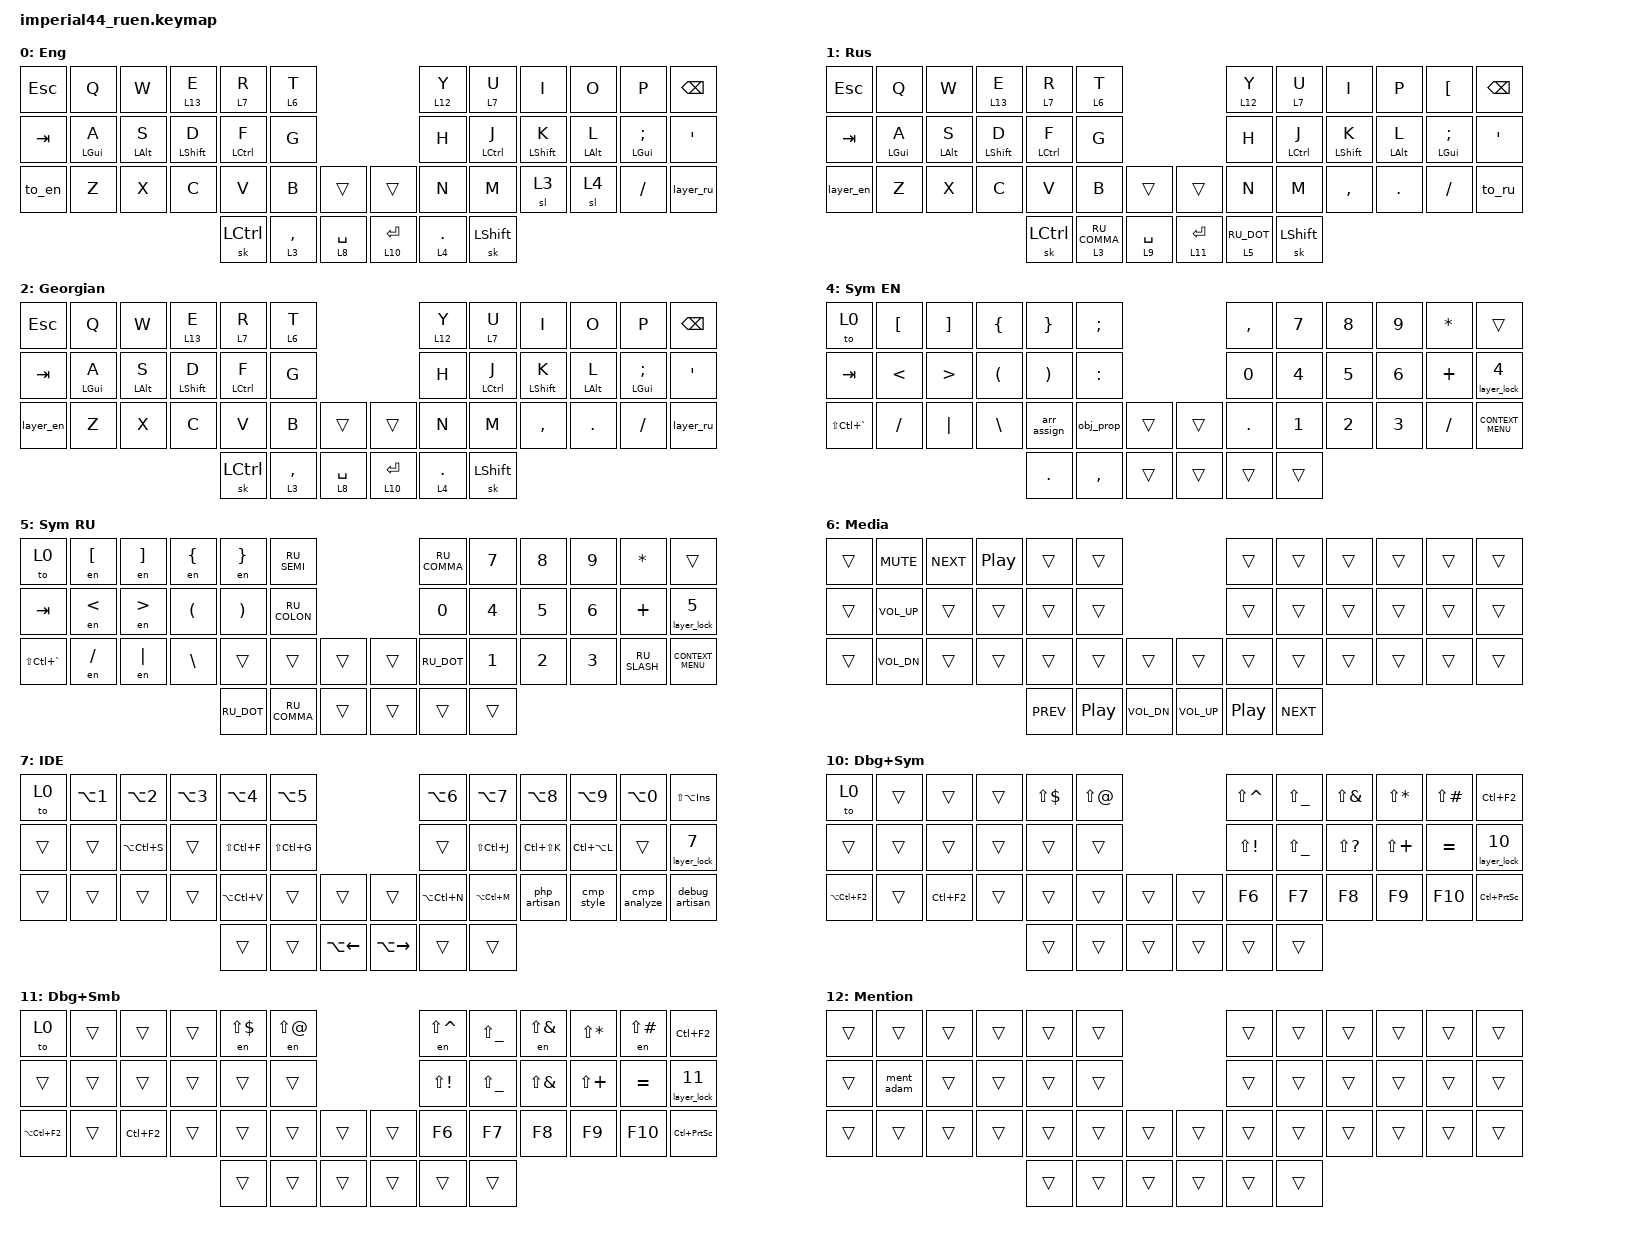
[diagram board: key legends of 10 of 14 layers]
#include "keys_ru.h"
#include <behaviors.dtsi>
#include <dt-bindings/zmk/keys.h>
#include <dt-bindings/zmk/pointing.h>

/ {
    combos {
        compatible = "zmk,combos";

        combo_cut {
            bindings = <&kp LC(X)>;
            key-positions = <26 27>;
            layers = <0 1>;
        };

        combo_copy {
            bindings = <&kp LC(C)>;
            key-positions = <27 28>;
            layers = <0 1>;
        };

        combo_paste {
            bindings = <&kp LC(V)>;
            key-positions = <28 38>;
            layers = <0 1>;
        };

        combo_dash {
            bindings = <&kp MINUS>;
            key-positions = <4 5>;
            layers = <0 1>;
            timeout-ms = <30>;
        };

        combo_grave {
            bindings = <&kp GRAVE>;
            key-positions = <4 3>;
            layers = <0 1>;
            timeout-ms = <30>;
        };

        combo_underscore {
            bindings = <&kp UNDER>;
            key-positions = <6 7>;
            layers = <0 1>;
            timeout-ms = <30>;
        };

        combo_ru_scha {
            bindings = <&kp O>;
            key-positions = <7 8>;
            layers = <1>;
        };

        combo_ru_hard_b {
            bindings = <&kp RIGHT_BRACKET>;
            key-positions = <33 34>;
            layers = <1>;
        };

        geo_lng {
            bindings = <&layer_ge>;
            key-positions = <37 36>;
            layers = <0 1 2>;
        };
    };

    macros {
        to_ru: to_ru {
            compatible = "zmk,behavior-macro";
            #binding-cells = <0>;
            bindings = <&kp LS(LC(N2))>;
            label = "TO_RU";
            wait-ms = <0>;
            tap-ms = <30>;
        };

        to_en: to_en {
            compatible = "zmk,behavior-macro";
            #binding-cells = <0>;
            bindings = <&kp LS(LC(N1))>;
            label = "TO_EN";
            wait-ms = <0>;
            tap-ms = <30>;
        };

        layer_en: layer_en {
            compatible = "zmk,behavior-macro";
            #binding-cells = <0>;
            bindings = <&to 0 &to_en>;
            label = "LAYER_EN";
            wait-ms = <0>;
            tap-ms = <30>;
        };

        layer_ru: layer_ru {
            compatible = "zmk,behavior-macro";
            #binding-cells = <0>;
            bindings = <&to 1 &to_ru>;
            label = "LAYER_RU";
            tap-ms = <30>;
            wait-ms = <0>;
        };

        en: en {
            compatible = "zmk,behavior-macro-one-param";
            #binding-cells = <1>;
            bindings =
                <&to_en>,
                <&macro_press>,
                <&macro_param_1to1 &kp MACRO_PLACEHOLDER>,
                <&macro_pause_for_release>,
                <&macro_release>,
                <&macro_param_1to1 &kp MACRO_PLACEHOLDER>,
                <&macro_tap>,
                <&to_ru>;

            label = "EN";
            wait-ms = <0>;
            tap-ms = <30>;
        };

        row_: row_ {
            compatible = "zmk,behavior-macro-one-param";
            #binding-cells = <1>;
            bindings = <&kp HOME &kp LS(END) &macro_param_1to1 &kp MACRO_PLACEHOLDER>;
            label = "ROW_";
        };

        row_copy: row_copy {
            compatible = "zmk,behavior-macro";
            #binding-cells = <0>;
            bindings = <&row_ LC(C)>;
            label = "ROW_COPY";
        };

        row_cut: row_cut {
            compatible = "zmk,behavior-macro";
            #binding-cells = <0>;
            bindings = <&row_ LC(X)>;
            label = "ROW_CUT";
        };

        arr_assign: arr_assign {
            compatible = "zmk,behavior-macro";
            #binding-cells = <0>;
            bindings = <&to_en &kp EQUAL &kp GREATER_THAN>;
            label = "ARR_ASSIGN";
        };

        obj_prop: obj_prop {
            compatible = "zmk,behavior-macro";
            #binding-cells = <0>;
            bindings = <&to_en &kp MINUS &kp GT>;
            label = "OBJ_PROP";
        };

        php_artisan: php_artisan {
            compatible = "zmk,behavior-macro";
            #binding-cells = <0>;
            bindings = <&to_en &kp P &kp H &kp P &kp SPACE &kp A &kp R &kp T &kp I &kp S &kp A &kp N &kp SPACE>;
            label = "PHP_ARTISAN";
        };

        cmp_style: cmp_style {
            compatible = "zmk,behavior-macro";
            #binding-cells = <0>;
            bindings = <&to_en &kp C &kp O &kp M &kp P &kp O &kp S &kp E &kp R &kp SPACE &kp S &kp T &kp Y &kp L &kp E>;
            label = "CMP_STYLE";
        };

        cmp_analyze: cmp_analyze {
            compatible = "zmk,behavior-macro";
            #binding-cells = <0>;
            bindings = <&to_en &kp C &kp O &kp M &kp P &kp O &kp S &kp E &kp R &kp SPACE &kp A &kp N &kp A &kp L &kp Y &kp Z &kp E>;
            label = "CMP_ANALYZE";
        };

        ment_adam: ment_adam {
            compatible = "zmk,behavior-macro";
            #binding-cells = <0>;
            bindings = <&kp AT &kp LS(A) &kp D &kp A &kp M>;
            label = "MENT_ADAM";
        };

        arr_assign_ru: arr_assign_ru {
            compatible = "zmk,behavior-macro";
            #binding-cells = <0>;
            bindings = <&to_en &kp EQUAL &kp GREATER_THAN &to_ru>;
            label = "ARR_ASSIGN_RU";
        };

        obj_prop_ru: obj_prop_ru {
            compatible = "zmk,behavior-macro";
            #binding-cells = <0>;
            bindings = <&to_en &kp MINUS &kp GT &to_ru>;
            label = "OBJ_PROP_RU";
        };

        debug_artisan: debug_artisan {
            compatible = "zmk,behavior-macro";
            #binding-cells = <0>;
            bindings = <&kp P &kp H &kp P &kp MINUS &kp D &kp SPACE &kp A &kp R &kp T &kp I &kp S &kp A &kp N &kp SPACE>;
            label = "DEBUG_ARTISAN";
        };

        to_ge: to_ge {
            compatible = "zmk,behavior-macro";
            #binding-cells = <0>;
            bindings = <&kp LS(LC(N3))>;
            label = "TO_GE";
            wait-ms = <0>;
            tap-ms = <30>;
        };

        layer_ge: layer_ge {
            compatible = "zmk,behavior-macro";
            #binding-cells = <0>;
            bindings = <&to 2 &to_ge>;
            label = "LAYER_GE";
            tap-ms = <30>;
            wait-ms = <0>;
        };
    };

    behaviors {
        hrm: hrm {
            compatible = "zmk,behavior-hold-tap";
            label = "HRM";
            bindings = <&kp>, <&kp>;

            #binding-cells = <2>;
            tapping-term-ms = <200>;
            flavor = "tap-preferred";
            require-prior-idle-ms = <125>;
            quick-tap-ms = <200>;
        };

        row_cut_copy: row_cut_copy {
            compatible = "zmk,behavior-tap-dance";
            label = "ROW_CUT_COPY";
            #binding-cells = <0>;
            bindings = <&row_copy>, <&row_cut>;
        };

        tog_layer_on: tog_layer_on {
            compatible = "zmk,behavior-toggle-layer";
            label = "TOG_LAYER_ON";
            #binding-cells = <1>;
        };

        layer_lock: layer_lock {
            compatible = "zmk,behavior-toggle-layer";
            label = "LAYER_LOCK";
            #binding-cells = <1>;
            toggle-mode = "on";
            locking;
        };
    };

    keymap {
        compatible = "zmk,keymap";

        en {
            bindings = <
&kp ESC  &kp Q            &kp W            &lt 13 E           &lt 7 R              &lt 6 T                                   &lt 12 Y   &lt 7 U              &kp I              &kp O            &kp P               &kp BACKSPACE
&kp TAB  &hrm LEFT_GUI A  &hrm LEFT_ALT S  &hrm LEFT_SHIFT D  &hrm LEFT_CONTROL F  &kp G                                     &kp H      &hrm LEFT_CONTROL J  &hrm LEFT_SHIFT K  &hrm LEFT_ALT L  &hrm LEFT_GUI SEMI  &kp SINGLE_QUOTE
&to_en   &kp Z            &kp X            &kp C              &kp V                &kp B        &trans         &trans        &kp N      &kp M                &sl 3              &sl 4            &kp SLASH           &layer_ru
                                                              &sk LCTRL            &lt 3 COMMA  &lt 8 SPACE    &lt 10 ENTER  &lt 4 DOT  &sk LEFT_SHIFT
            >;

            display-name = "Eng";
        };

        ru {
            display-name = "Rus";
            bindings = <
&kp ESC    &kp Q            &kp W            &lt 13 E           &lt 7 R              &lt 6 T                                      &lt 12 Y      &lt 7 U              &kp I              &kp P            &kp LBKT            &kp BACKSPACE
&kp TAB    &hrm LEFT_GUI A  &hrm LEFT_ALT S  &hrm LEFT_SHIFT D  &hrm LEFT_CONTROL F  &kp G                                        &kp H         &hrm LEFT_CONTROL J  &hrm LEFT_SHIFT K  &hrm LEFT_ALT L  &hrm LEFT_GUI SEMI  &kp SINGLE_QUOTE
&layer_en  &kp Z            &kp X            &kp C              &kp V                &kp B           &trans         &trans        &kp N         &kp M                &kp COMMA          &kp DOT          &kp SLASH           &to_ru
                                                                &sk LCTRL            &lt 3 RU_COMMA  &lt 9 SPACE    &lt 11 ENTER  &lt 5 RU_DOT  &sk LEFT_SHIFT
            >;
        };

        GE {
            display-name = "Georgian";
            bindings = <
&kp ESC    &kp Q            &kp W            &lt 13 E           &lt 7 R              &lt 6 T                                   &lt 12 Y   &lt 7 U              &kp I              &kp O            &kp P               &kp BACKSPACE
&kp TAB    &hrm LEFT_GUI A  &hrm LEFT_ALT S  &hrm LEFT_SHIFT D  &hrm LEFT_CONTROL F  &kp G                                     &kp H      &hrm LEFT_CONTROL J  &hrm LEFT_SHIFT K  &hrm LEFT_ALT L  &hrm LEFT_GUI SEMI  &kp SINGLE_QUOTE
&layer_en  &kp Z            &kp X            &kp C              &kp V                &kp B        &trans         &trans        &kp N      &kp M                &kp COMMA          &kp DOT          &kp SLASH           &layer_ru
                                                                &sk LCTRL            &lt 3 COMMA  &lt 8 SPACE    &lt 10 ENTER  &lt 4 DOT  &sk LEFT_SHIFT
            >;
        };

        nav {
            bindings = <
&to 0                  &kp LS(LA(LC(LEFT_BRACKET)))  &kp LS(LA(LC(UP)))    &kp LS(LC(I))  &kp LS(F6)  &kp LC(F12)                             &kp INS            &kp HOME      &kp PAGE_DOWN  &kp PAGE_UP  &kp END        &trans
&kp LA(LC(LS(GRAVE)))  &kp LS(LA(LC(P)))             &kp LS(LA(LC(DOWN)))  &kp LC(Y)      &kp LC(Q)   &row_cut_copy                           &kp LS(LC(M))      &kp LEFT      &kp DOWN       &kp UP       &kp RIGHT      &layer_lock 3
&kp LA(INSERT)         &kp LA(LC(Z))                 &kp LC(LS(F7))        &mkp MB4       &mkp MB5    &kp LA(F7)     &trans    &trans         &kp DEL            &kp LC(LEFT)  &kp LA(DOWN)   &kp LA(UP)   &kp LC(RIGHT)  &kp LS(LA(LC(F12)))
                                                                                          &trans      &trans         &trans    &kp BACKSPACE  &kp LC(BACKSPACE)  &kp LC(DEL)
            >;

            display-name = "Nav";
        };

        sym_en {
            bindings = <
&to 0              &kp LEFT_BRACKET  &kp RIGHT_BRACKET  &kp LEFT_BRACE  &kp RIGHT_BRACE  &kp SEMI                     &kp COMMA  &kp N7  &kp N8  &kp N9  &kp ASTERISK  &trans
&kp TAB            &kp LESS_THAN     &kp GREATER_THAN   &kp LPAR        &kp RPAR         &kp COLON                    &kp N0     &kp N4  &kp N5  &kp N6  &kp PLUS      &layer_lock 4
&kp LS(LC(GRAVE))  &kp FSLH          &kp PIPE           &kp BSLH        &arr_assign      &obj_prop  &trans    &trans  &kp DOT    &kp N1  &kp N2  &kp N3  &kp SLASH     &kp K_CONTEXT_MENU
                                                                        &kp DOT          &kp COMMA  &trans    &trans  &trans     &trans
            >;

            display-name = "Sym EN";
        };

        sym_ru {
            display-name = "Sym RU";
            bindings = <
&to 0              &en LEFT_BRACKET  &en RIGHT_BRACKET  &en LEFT_BRACE  &en RIGHT_BRACE  &kp RU_SEMI                     &kp RU_COMMA  &kp N7  &kp N8  &kp N9  &kp ASTERISK  &trans
&kp TAB            &en LESS_THAN     &en GREATER_THAN   &kp LPAR        &kp RPAR         &kp RU_COLON                    &kp N0        &kp N4  &kp N5  &kp N6  &kp PLUS      &layer_lock 5
&kp LS(LC(GRAVE))  &en FSLH          &en PIPE           &kp BSLH        &trans           &trans        &trans    &trans  &kp RU_DOT    &kp N1  &kp N2  &kp N3  &kp RU_SLASH  &kp K_CONTEXT_MENU
                                                                        &kp RU_DOT       &kp RU_COMMA  &trans    &trans  &trans        &trans
            >;
        };

        media {
            display-name = "Media";
            bindings = <
&trans  &kp C_MUTE       &kp C_NEXT  &kp C_PLAY_PAUSE  &trans      &trans                                          &trans            &trans      &trans  &trans  &trans  &trans
&trans  &kp C_VOLUME_UP  &trans      &trans            &trans      &trans                                          &trans            &trans      &trans  &trans  &trans  &trans
&trans  &kp C_VOL_DN     &trans      &trans            &trans      &trans            &trans          &trans        &trans            &trans      &trans  &trans  &trans  &trans
                                                       &kp C_PREV  &kp C_PLAY_PAUSE  &kp C_VOL_DN    &kp C_VOL_UP  &kp C_PLAY_PAUSE  &kp C_NEXT
            >;
        };

        ide {
            bindings = <
&to 0   &kp LA(N1)  &kp LA(N2)     &kp LA(N3)  &kp LA(N4)     &kp LA(N5)                                    &kp LA(N6)     &kp LA(N7)     &kp LA(N8)     &kp LA(N9)     &kp LA(N0)    &kp LS(LA(INS))
&trans  &trans      &kp LA(LC(S))  &trans      &kp LS(LC(F))  &kp LS(LC(G))                                 &trans         &kp LS(LC(J))  &kp LC(LS(K))  &kp LC(LA(L))  &trans        &layer_lock 7
&trans  &trans      &trans         &trans      &kp LA(LC(V))  &trans         &trans          &trans         &kp LA(LC(N))  &kp LA(LC(M))  &php_artisan   &cmp_style     &cmp_analyze  &debug_artisan
                                               &trans         &trans         &kp LA(LEFT)    &kp LA(RIGHT)  &trans         &trans
            >;

            display-name = "IDE";
        };

        mouse+sym_en {
            bindings = <
&to 0                  &kp LS(DQT)  &kp LS(DLLR)  &kp SQT   &kp MINUS  &kp LS(PRCNT)                      &kp LS(DQT)       &kp SQT             &trans          &trans        &trans              &trans
&kp LA(LC(Y))          &kp LS(AT)   &kp LS(DLLR)  &kp SEMI  &kp MINUS  &kp COLON                          &msc MOVE_Y(10)   &mmv MOVE_LEFT      &mmv MOVE_DOWN  &mmv MOVE_UP  &mmv MOVE_RIGHT     &layer_lock 8
&kp LA(LC(LG(SPACE)))  &kp F1       &kp F2        &kp F3    &kp F4     &kp F5         &trans    &trans    &msc MOVE_Y(-10)  &kp LS(LA(LC(F3)))  &trans          &trans        &kp LS(LA(LC(F4)))  &kp LC(F11)
                                                            &trans     &trans         &trans    &mkp MB1  &mkp MB2          &trans
            >;

            label = "Mouse+Sym";
        };

        mouse+sym_ru {
            bindings = <
&to 0                  &kp LS(AT_SIGN)  &en LS(DLLR)  &en SQT   &kp MINUS  &kp LS(PRCNT)                      &kp LS(AT_SIGN)   &en SQT             &trans          &trans        &trans              &trans
&kp LA(LC(Y))          &en LS(AT)       &en LS(DLLR)  &en SEMI  &kp MINUS  &kp LS(N6)                         &msc MOVE_Y(10)   &mmv MOVE_LEFT      &mmv MOVE_DOWN  &mmv MOVE_UP  &mmv MOVE_RIGHT     &layer_lock 9
&kp LA(LC(LG(SPACE)))  &kp F1           &kp F2        &kp F3    &kp F4     &kp F5         &trans    &trans    &msc MOVE_Y(-10)  &kp LS(LA(LC(F3)))  &trans          &trans        &kp LS(LA(LC(F4)))  &kp LC(F11)
                                                                &trans     &trans         &trans    &mkp MB1  &mkp MB2          &trans
            >;

            label = "Mouse+Smb";
        };

        debugger+sym_en {
            bindings = <
&to 0           &trans  &trans      &trans  &kp LS(DLLR)  &kp LS(AT)                    &kp LS(CARET)  &kp LS(UNDER)  &kp LS(AMPS)   &kp LS(STAR)  &kp LS(POUND)  &kp LC(F2)
&trans          &trans  &trans      &trans  &trans        &trans                        &kp LS(EXCL)   &kp LS(UNDER)  &kp LS(QMARK)  &kp LS(PLUS)  &kp EQUAL      &layer_lock 10
&kp LA(LC(F2))  &trans  &kp LC(F2)  &trans  &trans        &trans      &trans    &trans  &kp F6         &kp F7         &kp F8         &kp F9        &kp F10        &kp LC(PRINTSCREEN)
                                            &trans        &trans      &trans    &trans  &trans         &trans
            >;

            label = "Dbg+Sym";
        };

        debugger+sym_ru {
            bindings = <
&to 0           &trans  &trans      &trans  &en LS(DLLR)  &en LS(AT)                    &en LS(CARET)  &kp LS(UNDER)  &en LS(AMPS)       &kp LS(STAR)  &en LS(POUND)  &kp LC(F2)
&trans          &trans  &trans      &trans  &trans        &trans                        &kp LS(EXCL)   &kp LS(UNDER)  &kp LS(AMPERSAND)  &kp LS(PLUS)  &kp EQUAL      &layer_lock 11
&kp LA(LC(F2))  &trans  &kp LC(F2)  &trans  &trans        &trans      &trans    &trans  &kp F6         &kp F7         &kp F8             &kp F9        &kp F10        &kp LC(PRINTSCREEN)
                                            &trans        &trans      &trans    &trans  &trans         &trans
            >;

            label = "Dbg+Smb";
        };

        mentions {
            bindings = <
&trans  &trans      &trans  &trans  &trans  &trans                        &trans  &trans  &trans  &trans  &trans  &trans
&trans  &ment_adam  &trans  &trans  &trans  &trans                        &trans  &trans  &trans  &trans  &trans  &trans
&trans  &trans      &trans  &trans  &trans  &trans      &trans    &trans  &trans  &trans  &trans  &trans  &trans  &trans
                                    &trans  &trans      &trans    &trans  &trans  &trans
            >;

            label = "Mention";
        };

        win_manage {
            bindings = <
&trans  &kp F23  &kp F24  &trans  &trans  &trans                    &trans  &kp LG(LEFT)        &kp LG(DOWN)  &kp LG(UP)  &kp LG(RIGHT)       &kp LA(F4)
&trans  &trans   &trans   &trans  &trans  &trans                    &trans  &kp LS(LG(LEFT))    &kp LG(DOWN)  &kp LG(UP)  &kp LS(LG(RIGHT))   &trans
&trans  &trans   &trans   &trans  &trans  &trans  &none     &trans  &trans  &kp LS(LA(LC(F3)))  &trans        &trans      &kp LS(LA(LC(F4)))  &trans
                                  &trans  &trans  &trans    &trans  &trans  &trans
            >;

            label = "Win Mng";
        };
    };

    conditional_layers { compatible = "zmk,conditional-layers"; };
};
